# PIC32MX350F128L device description
Architecture: MIPS; Family: PIC32MX; Series: PIC32MX
Registers are 32-bit, read-write, no defined reset value unless marked. A register's access mark holds for its fields unless they carry their own. Offsets are from the block's base; [hi:lo] are bit positions; lines under a group give offsets from that group; {n}, {i} and the like mark numbered series.

## INT
Instances: INT 0x1f881000 in periph2
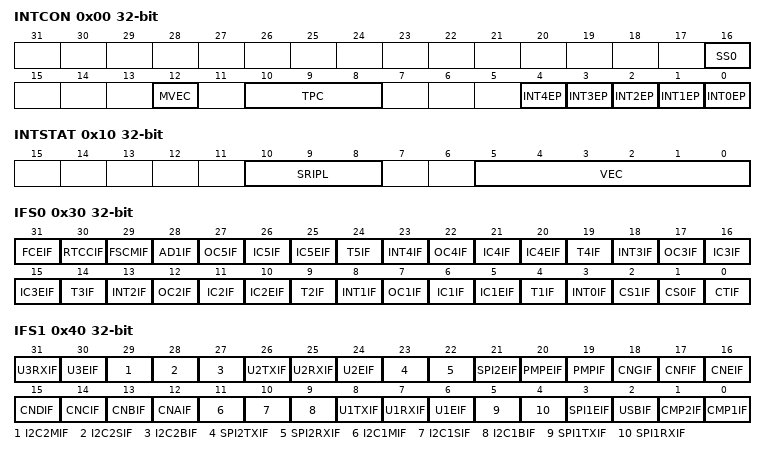
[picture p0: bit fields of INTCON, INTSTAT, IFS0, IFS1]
0x00 INTCON — Interrupt Control Register
  [16] SS0 — Single Vector Shadow Register Set bit
    1=Single vector is presented with a shadow register set; 0=Single vector is not presented with a shadow register set
  [12] MVEC — Multi Vector Configuration bit
    1=Interrupt controller configured for multi vectored mode; 0=Interrupt controller configured for single vectored mode
  [10:8] TPC — Interrupt Proximity Timer Control bits
    {v}=Interrupts of group priority {v} or lower start the Interrupt Proximity timer (v=2..7); 1=Interrupts of group priority 1 start the Interrupt Proximity timer; 0=Disables Interrupt Proximity timer
  [n] INT{n}EP (n=0..4) — External Interrupt {n} Edge
    1=Rising edge; 0=Falling edge
0x10 INTSTAT — Interrupt Status Register
  [10:8] SRIPL — Requested Priority Level bits
    {v}=The priority level of the latest interrupt presented to the CPU is {v} (v=0..7)
  [5:0] VEC — Interrupt Vector bits
    {v}=The interrupt vector that is presented to the CPU is {v} (v=0..31)
0x20 IPTMR — Interrupt Proximity Timer Register
  [31:0] IPTMR — Interrupt Proximity Timer Reload bits
    0=Timer reload value is 0; 1=Timer reload value is 1; 0xffffffff=Timer reload value is 0xffffffff
0x30 IFS0 — Interrupt Flag Status Register
  [31] FCEIF, [30] RTCCIF, [29] FSCMIF, [28] AD1IF, [5n+2] OC{n}IF (n=1..5), [5n+1] IC{n}IF (n=1..5), [5n] IC{n}EIF (n=1..5), [5n-1] T{n}IF (n=1..5), [5n+3] INT{n}IF (n=0..4), [2] CS1IF, [1] CS0IF, [0] CTIF
0x40 IFS1 — Interrupt Flag Status Register
  [31] U3RXIF, [30] U3EIF, [29] I2C2MIF, [28] I2C2SIF, [27] I2C2BIF, [26] U2TXIF, [25] U2RXIF, [24] U2EIF, [23] SPI2TXIF, [22] SPI2RXIF, [21] SPI2EIF, [20] PMPEIF, [19] PMPIF, [18] CNGIF, [17] CNFIF, [16] CNEIF, [15] CNDIF, [14] CNCIF, [13] CNBIF, [12] CNAIF, [11] I2C1MIF, [10] I2C1SIF, [9] I2C1BIF, [8] U1TXIF, [7] U1RXIF, [6] U1EIF, [5] SPI1TXIF, [4] SPI1RXIF, [3] SPI1EIF, [2] USBIF, [1] CMP2IF, [0] CMP1IF
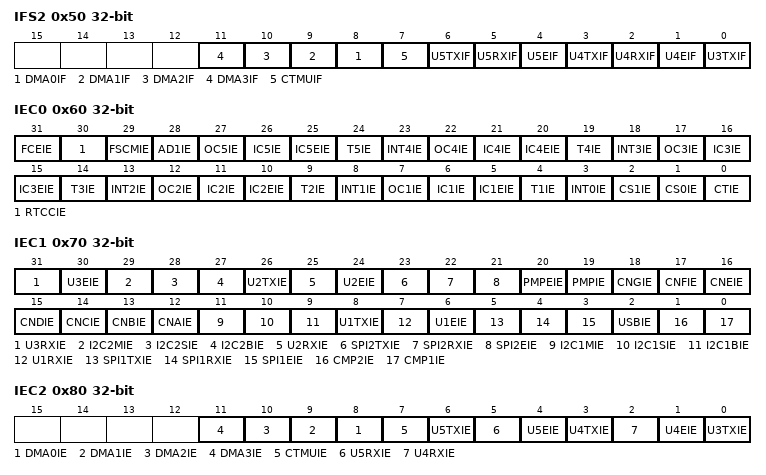
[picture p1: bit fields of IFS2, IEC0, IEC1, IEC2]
0x50 IFS2 — Interrupt Flag Status Register
  [n+8] DMA{n}IF (n=0..3), [7] CTMUIF, [6] U5TXIF, [5] U5RXIF, [4] U5EIF, [3] U4TXIF, [2] U4RXIF, [1] U4EIF, [0] U3TXIF
0x60 IEC0 — Interrupt Enable Control Register
  [31] FCEIE, [30] RTCCIE, [29] FSCMIE, [28] AD1IE, [5n+2] OC{n}IE (n=1..5), [5n+1] IC{n}IE (n=1..5), [5n] IC{n}EIE (n=1..5), [5n-1] T{n}IE (n=1..5), [5n+3] INT{n}IE (n=0..4), [2] CS1IE, [1] CS0IE, [0] CTIE
0x70 IEC1 — Interrupt Enable Control Register
  [31] U3RXIE, [30] U3EIE, [29] I2C2MIE, [28] I2C2SIE, [27] I2C2BIE, [26] U2TXIE, [25] U2RXIE, [24] U2EIE, [23] SPI2TXIE, [22] SPI2RXIE, [21] SPI2EIE, [20] PMPEIE, [19] PMPIE, [18] CNGIE, [17] CNFIE, [16] CNEIE, [15] CNDIE, [14] CNCIE, [13] CNBIE, [12] CNAIE, [11] I2C1MIE, [10] I2C1SIE, [9] I2C1BIE, [8] U1TXIE, [7] U1RXIE, [6] U1EIE, [5] SPI1TXIE, [4] SPI1RXIE, [3] SPI1EIE, [2] USBIE, [1] CMP2IE, [0] CMP1IE
0x80 IEC2 — Interrupt Enable Control Register
  [n+8] DMA{n}IE (n=0..3), [7] CTMUIE, [6] U5TXIE, [5] U5RXIE, [4] U5EIE, [3] U4TXIE, [2] U4RXIE, [1] U4EIE, [0] U3TXIE
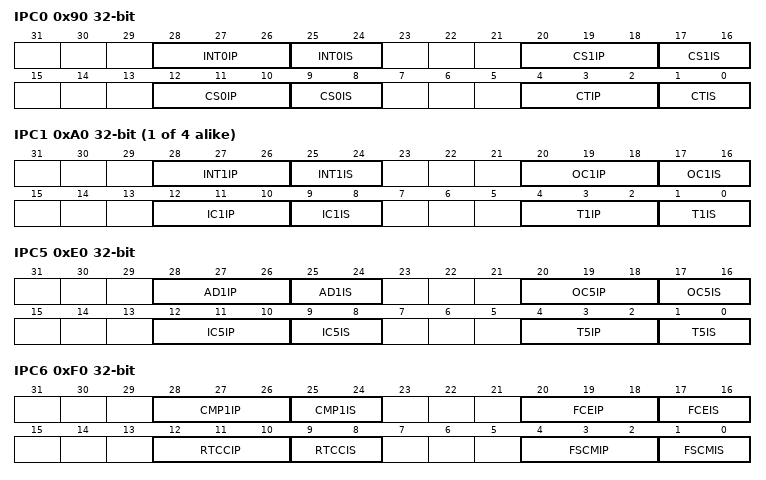
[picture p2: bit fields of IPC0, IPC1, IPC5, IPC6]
0x90 IPC0 — Interrupt Priority Control Register
  [28:26] INT0IP, [25:24] INT0IS, [20:18] CS1IP, [17:16] CS1IS, [12:10] CS0IP, [9:8] CS0IS, [4:2] CTIP, [1:0] CTIS
{0x90+0x10*i} IPC{i} (i=1..4) — Interrupt Priority Control Register
  [28:26] INT{i}IP, [25:24] INT{i}IS, [20:18] OC{i}IP, [17:16] OC{i}IS, [12:10] IC{i}IP, [9:8] IC{i}IS, [4:2] T{i}IP, [1:0] T{i}IS
0xE0 IPC5 — Interrupt Priority Control Register
  [28:26] AD1IP, [25:24] AD1IS, [20:18] OC5IP, [17:16] OC5IS, [12:10] IC5IP, [9:8] IC5IS, [4:2] T5IP, [1:0] T5IS
0xF0 IPC6 — Interrupt Priority Control Register
  [28:26] CMP1IP, [25:24] CMP1IS, [20:18] FCEIP, [17:16] FCEIS, [12:10] RTCCIP, [9:8] RTCCIS, [4:2] FSCMIP, [1:0] FSCMIS
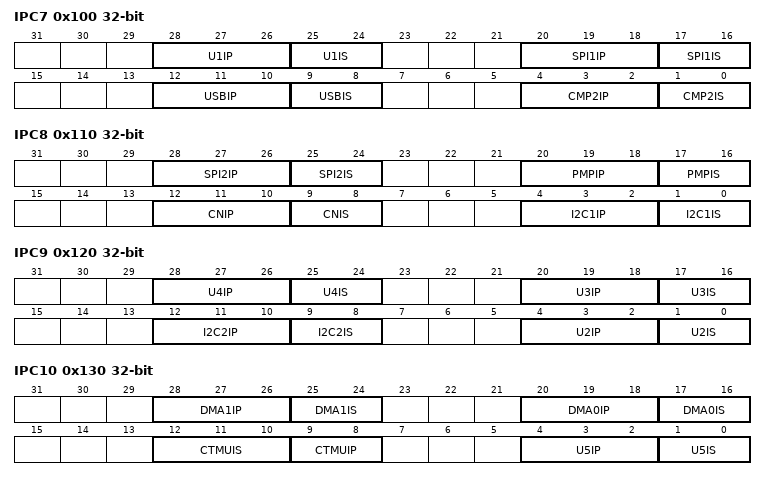
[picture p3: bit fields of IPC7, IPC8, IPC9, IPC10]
0x100 IPC7 — Interrupt Priority Control Register
  [28:26] U1IP, [25:24] U1IS, [20:18] SPI1IP, [17:16] SPI1IS, [12:10] USBIP, [9:8] USBIS, [4:2] CMP2IP, [1:0] CMP2IS
0x110 IPC8 — Interrupt Priority Control Register
  [28:26] SPI2IP, [25:24] SPI2IS, [20:18] PMPIP, [17:16] PMPIS, [12:10] CNIP, [9:8] CNIS, [4:2] I2C1IP, [1:0] I2C1IS
0x120 IPC9 — Interrupt Priority Control Register
  [28:26] U4IP, [25:24] U4IS, [20:18] U3IP, [17:16] U3IS, [12:10] I2C2IP, [9:8] I2C2IS, [4:2] U2IP, [1:0] U2IS
0x130 IPC10 — Interrupt Priority Control Register
  [28:26] DMA1IP, [25:24] DMA1IS, [20:18] DMA0IP, [17:16] DMA0IS, [12:10] CTMUIS, [9:8] CTMUIP, [4:2] U5IP, [1:0] U5IS
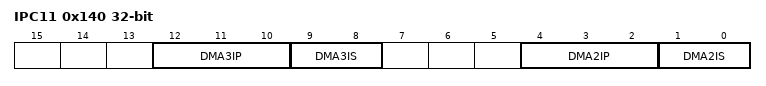
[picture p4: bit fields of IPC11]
0x140 IPC11 — Interrupt Priority Control Register
  [12:10] DMA3IP, [9:8] DMA3IS, [4:2] DMA2IP, [1:0] DMA2IS

## Notices in the file
Copyright (c) 2019 Microchip Technology Inc.
SPDX-License-Identifier: Apache-2.0
Licensed under the Apache License, Version 2.0 (the "License");
you may not use this file except in compliance with the License.
You may obtain a copy of the License at
http://www.apache.org/licenses/LICENSE-2.0
Unless required by applicable law or agreed to in writing, software
distributed under the License is distributed on an "AS IS" BASIS,
WITHOUT WARRANTIES OR CONDITIONS OF ANY KIND, either express or implied.
See the License for the specific language governing permissions and
limitations under the License.
